AUTOSAR XML (schema 4-2-2)
package /ComponentTypes
  application sw component type SensorComponent
    provide port SensorData: provided-interface=SensorDataInterface
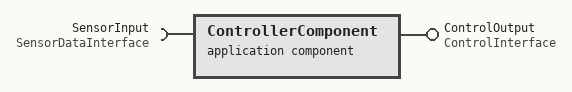
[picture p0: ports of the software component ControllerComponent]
  application sw component type ControllerComponent
    require port SensorInput: required-interface=SensorDataInterface
    provide port ControlOutput: provided-interface=ControlInterface
  composition sw component type SystemComposition
    component Sensor: type=SensorComponent
    component Controller: type=ControllerComponent
package /Interfaces
  sender receiver interface SensorDataInterface
    data Temperature
    data Pressure
  sender receiver interface ControlInterface
    data ControlSignal
  client server interface DiagnosticInterface
package /SystemSignals
  system signal TemperatureSignal
  system signal PressureSignal
  i signal ControlSignalPDU
